# ESP32-H21 register map
Vendor: ESPRESSIF SYSTEMS (SHANGHAI) CO., LTD.; Series: ESP32 H-Series; File version: 1
CPU: RV32IMAC r0p0, little endian, no MPU, no FPU, 0 interrupt priority bits
Address unit: 32 bits
Registers are 32-bit, read-write, reset 0x0 unless marked. A register's access mark holds for its fields unless they carry their own. Offsets are from the block's base; [hi:lo] are bit positions; {n}, {i} and the like mark numbered series.

## PAU — PAU Peripheral
Base 0x60093000
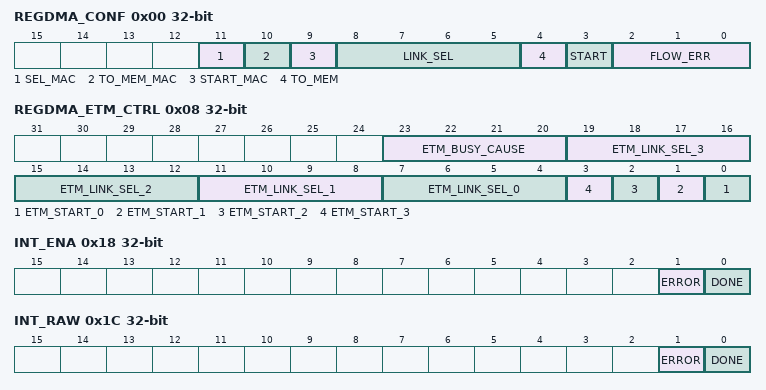
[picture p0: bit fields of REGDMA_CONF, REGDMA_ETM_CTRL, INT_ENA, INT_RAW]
0x00 REGDMA_CONF access per field — Peri backup control register
  [11] SEL_MAC rw — mac hw/sw select
  [10] TO_MEM_MAC rw — mac sw backup direction(reg to mem / mem to reg)
  [9] START_MAC wo — mac sw backup start signal
  [8:5] LINK_SEL rw — Link select
  [4] TO_MEM rw — backup direction(reg to mem / mem to reg)
  [3] START wo — backup start signal
  [2:0] FLOW_ERR ro — backup error type
0x04 REGDMA_CLK_CONF — Clock control register
  [0] CLK_EN — clock enable
0x08 REGDMA_ETM_CTRL access per field — ETM start ctrl reg
  [23:20] ETM_BUSY_CAUSE ro — debug
  [4n+7:4n+4] ETM_LINK_SEL_{n} rw (n=0..3) — etm_link sel
  [n] ETM_START_{n} wo (n=0..3) — etm_start_{n} reg
0x0C REGDMA_CURRENT_LINK_ADDR ro — current link addr
  [31:0] CURRENT_LINK_ADDR — current link addr reg
0x10 REGDMA_PERI_ADDR ro — Backup addr
  [31:0] PERI_ADDR — peri addr reg
0x14 REGDMA_MEM_ADDR ro — mem addr
  [31:0] MEM_ADDR — mem addr reg
0x18 INT_ENA — Read only register for error and done
  [1] ERROR — error flag
  [0] DONE — backup done flag
0x1C INT_RAW — Read only register for error and done
  [1] ERROR — error flag
  [0] DONE — backup done flag
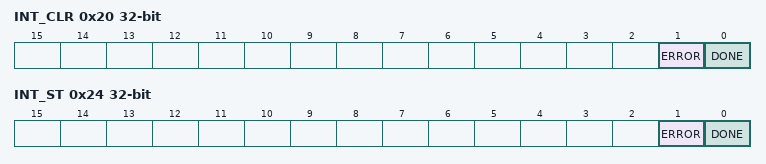
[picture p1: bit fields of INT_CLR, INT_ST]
0x20 INT_CLR wo — Read only register for error and done
  [1] ERROR write-1-clears — error flag
  [0] DONE write-1-clears — backup done flag
0x24 INT_ST ro — Read only register for error and done
  [1] ERROR — error flag
  [0] DONE — backup done flag
0x3FC DATE

## RSA — RSA (Rivest Shamir Adleman) Accelerator
Base 0x6008A000
{0x0+4i} M_MEM[{i}] (i=0..95) — Represents M
{0x200+4i} Z_MEM[{i}] (i=0..95) — Represents Z
{0x400+4i} Y_MEM[{i}] (i=0..95) — Represents Y
{0x600+4i} X_MEM[{i}] (i=0..95) — Represents X
0x800 M_PRIME — Represents M’
0x804 MODE — Configures RSA length
  [6:0] MODE — Configures the RSA length.
0x808 QUERY_CLEAN ro — RSA clean register
  [0] QUERY_CLEAN — Represents whether or not the RSA memory completes initialization. 0: Not complete 1: Completed
0x80C SET_START_MODEXP wo — Starts modular exponentiation
  [0] SET_START_MODEXP — Configure whether or not to start the modular exponentiation. 0: No effect 1: Start
0x810 SET_START_MODMULT wo — Starts modular multiplication
  [0] SET_START_MODMULT — Configure whether or not to start the modular multiplication. 0: No effect 1: Start
0x814 SET_START_MULT wo — Starts multiplication
  [0] SET_START_MULT — Configure whether or not to start the multiplication. 0: No effect 1: Start
0x818 QUERY_IDLE ro — Represents the RSA status
  [0] QUERY_IDLE — Represents the RSA status. 0: Busy 1: Idle
0x81C INT_CLR — Clears RSA interrupt
  [0] INT_CLR — Write 1 to clear the RSA interrupt.
0x820 CONSTANT_TIME reset 0x1 — Configures the constant_time option
  [0] CONSTANT_TIME — Configures the constant_time option. 0: Acceleration 1: No acceleration (default)
0x824 SEARCH_ENABLE — Configures the search option
  [0] SEARCH_ENABLE — Configure the search option. 0: No acceleration (default) 1: Acceleration This option should be used together with RSA_SEARCH_POS.
0x828 SEARCH_POS — Configures the search position
  [11:0] SEARCH_POS — Configures the starting address to start search. This field should be used together with RSA_SEARCH_ENABLE. The field is only valid when RSA_SEARCH_ENABLE is high.
0x82C INT_ENA — Enables the RSA interrupt
  [0] INT_ENA — Write 1 to enable the RSA interrupt.
0x830 DATE — Version control register

## SHA — SHA (Secure Hash Algorithm) Accelerator
Base 0x60089000
0x00 MODE — Initial configuration register.
  [2:0] MODE — Sha mode.
0x04 T_STRING — SHA 512/t configuration register 0.
  [31:0] T_STRING — Sha t_string (used if and only if mode == SHA_512/t).
0x08 T_LENGTH — SHA 512/t configuration register 1.
  [5:0] T_LENGTH — Sha t_length (used if and only if mode == SHA_512/t).
0x0C DMA_BLOCK_NUM — DMA configuration register 0.
  [5:0] DMA_BLOCK_NUM — Dma-sha block number.
0x10 START wo — Typical SHA configuration register 0.
  [0] START — Write 1 to start Typical SHA calculation.
0x14 CONTINUE wo — Typical SHA configuration register 1.
  [0] CONTINUE — Write 1 to continue Typical SHA calculation.
0x18 BUSY ro
  [0] STATE — Sha busy state. 1'b0: idle. 1'b1: busy.
0x1C DMA_START wo — DMA configuration register 1.
  [0] DMA_START — Start dma-sha.
0x20 DMA_CONTINUE wo — DMA configuration register 2.
  [0] DMA_CONTINUE — Continue dma-sha.
0x24 CLEAR_IRQ wo — Interrupt clear register.
  [0] CLEAR_INTERRUPT — Clear sha interrupt.
0x28 IRQ_ENA — Interrupt enable register.
  [0] INTERRUPT_ENA — Sha interrupt enable register. 1'b0: disable(default). 1'b1: enable.
0x2C DATE
{0x40+4i} H_MEM[{i}] (i=0..7) access not given — Sha H memory which contains intermediate hash or finial hash.
{0x80+4i} M_MEM[{i}] (i=0..15) access not given — Sha M memory which contains message.
